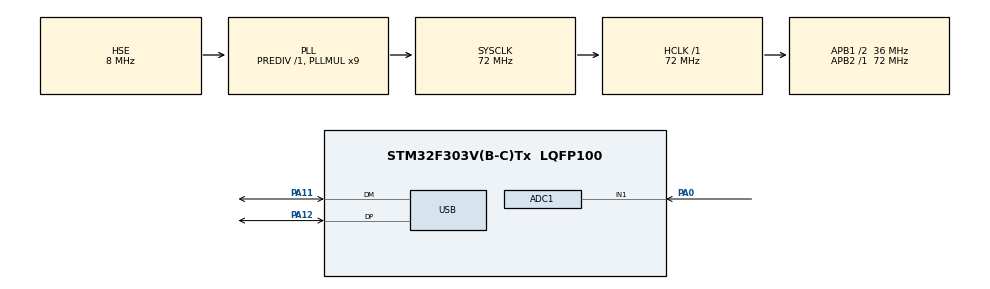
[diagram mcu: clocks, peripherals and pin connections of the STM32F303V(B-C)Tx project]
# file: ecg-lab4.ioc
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ADC1.Channel-0\#ChannelRegularConversion=ADC_CHANNEL_1
ADC1.ClockPrescaler=ADC_CLOCK_ASYNC_DIV1
ADC1.ContinuousConvMode=ENABLE
ADC1.DMAContinuousRequests=ENABLE
ADC1.ExternalTrigConv=ADC_EXTERNALTRIGCONV_T3_TRGO
ADC1.NbrOfConversionFlag=1
ADC1.Offset-0\#ChannelRegularConversion=0
ADC1.OffsetNumber-0\#ChannelRegularConversion=ADC_OFFSET_NONE
ADC1.Rank-0\#ChannelRegularConversion=1
ADC1.SamplingTime-0\#ChannelRegularConversion=ADC_SAMPLETIME_601CYCLES_5
ADC1.SamplingTimeOPAMP-0\#ChannelRegularConversion=ADC_SAMPLETIME_61CYCLES_5
ADC1.master=1
Dma.ADC1.0.Direction=DMA_PERIPH_TO_MEMORY
Dma.ADC1.0.Instance=DMA1_Channel1
Dma.ADC1.0.MemDataAlignment=DMA_MDATAALIGN_WORD
Dma.ADC1.0.MemInc=DMA_MINC_ENABLE
Dma.ADC1.0.Mode=DMA_CIRCULAR
Dma.ADC1.0.PeriphDataAlignment=DMA_PDATAALIGN_WORD
Dma.ADC1.0.PeriphInc=DMA_PINC_DISABLE
Dma.ADC1.0.Priority=DMA_PRIORITY_LOW
Dma.Request0=ADC1
Mcu.Family=STM32F3
Mcu.Name=STM32F303V(B-C)Tx
Mcu.Package=LQFP100
NVIC.DMA1_Channel1_IRQn=true\:0\:0\:false\:false\:true\:false\:true\:true
NVIC.PriorityGroup=NVIC_PRIORITYGROUP_0
NVIC.TIM3_IRQn=true\:0\:0\:false\:false\:true\:true\:true\:true
NVIC.USB_LP_CAN_RX0_IRQn=true\:0\:0\:false\:false\:true\:false\:true\:true
PA0.Mode=IN1-Single-Ended
PA0.Signal=ADC1_IN1
PA11.Mode=Device
PA11.Signal=USB_DM
PA12.Mode=Device
PA12.Signal=USB_DP
PF0-OSC_IN.Mode=HSE-External-Oscillator
PF0-OSC_IN.Signal=RCC_OSC_IN
PF1-OSC_OUT.Mode=HSE-External-Oscillator
PF1-OSC_OUT.Signal=RCC_OSC_OUT
ProjectManager.HeapSize=0x200
ProjectManager.StackSize=0x400
ProjectManager.TargetToolchain=MDK-ARM V5.32
RCC.AHBFreq_Value=72000000
RCC.APB1CLKDivider=RCC_HCLK_DIV2
RCC.APB1Freq_Value=36000000
RCC.APB1TimFreq_Value=72000000
RCC.APB2Freq_Value=72000000
RCC.APB2TimFreq_Value=72000000
RCC.CortexFreq_Value=72000000
RCC.HCLKFreq_Value=72000000
RCC.HSE_VALUE=8000000
RCC.HSI_VALUE=8000000
RCC.LSE_VALUE=32768
RCC.PLLMUL=RCC_PLL_MUL9
RCC.PRESCALERUSB=RCC_USBCLKSOURCE_PLL_DIV1_5
RCC.SYSCLKFreq_VALUE=72000000
RCC.SYSCLKSourceVirtual=RCC_SYSCLKSOURCE_PLLCLK
RCC.USBFreq_Value=48000000
TIM3.Period=71
TIM3.Prescaler=10000
TIM3.TIM_MasterOutputTrigger=TIM_TRGO_UPDATE
USB_DEVICE.CLASS_NAME_FS=CDC
USB_DEVICE.VirtualMode=Cdc
USB_DEVICE.VirtualModeFS=Cdc_FS
VP_TIM3_VS_ClockSourceINT.Mode=Internal
VP_USB_DEVICE_VS_USB_DEVICE_CDC_FS.Mode=CDC_FS
board=STM32F3DISCOVERY

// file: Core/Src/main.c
#include "main.h"
#include "usb_device.h"
#include "usbd_cdc_if.h"

ADC_HandleTypeDef hadc1;
DMA_HandleTypeDef hdma_adc1;

TIM_HandleTypeDef htim3;

void SystemClock_Config(void);
static void MX_GPIO_Init(void);
static void MX_DMA_Init(void);
static void MX_ADC1_Init(void);
static void MX_TIM3_Init(void);
uint32_t adc[1]={0};
uint8_t datos[2]={0,0};
void HAL_TIM_PeriodElapsedCallback(TIM_HandleTypeDef *htim){
	if(htim->Instance == htim3.Instance){
		datos[0] = (int)adc[0]/100;
		datos[1] = adc[0]-datos[0]*100;
		CDC_Transmit_FS(datos,sizeof(datos));
	}

}
int main(void)
{

  HAL_Init();
  SystemClock_Config();
  MX_GPIO_Init();
  MX_DMA_Init();
  MX_USB_DEVICE_Init();
  MX_ADC1_Init();
  MX_TIM3_Init();

	HAL_TIM_Base_Start_IT(&htim3);
	HAL_ADC_Start_DMA(&hadc1,adc,1);
  while (1)
  {

  }

}

void SystemClock_Config(void)
{
  RCC_OscInitTypeDef RCC_OscInitStruct = {0};
  RCC_ClkInitTypeDef RCC_ClkInitStruct = {0};
  RCC_PeriphCLKInitTypeDef PeriphClkInit = {0};

  /** Initializes the RCC Oscillators according to the specified parameters
  * in the RCC_OscInitTypeDef structure.
  */
  RCC_OscInitStruct.OscillatorType = RCC_OSCILLATORTYPE_HSE;
  RCC_OscInitStruct.HSEState = RCC_HSE_ON;
  RCC_OscInitStruct.HSEPredivValue = RCC_HSE_PREDIV_DIV1;
  RCC_OscInitStruct.HSIState = RCC_HSI_ON;
  RCC_OscInitStruct.PLL.PLLState = RCC_PLL_ON;
  RCC_OscInitStruct.PLL.PLLSource = RCC_PLLSOURCE_HSE;
  RCC_OscInitStruct.PLL.PLLMUL = RCC_PLL_MUL9;
  if (HAL_RCC_OscConfig(&RCC_OscInitStruct) != HAL_OK)
  {
    Error_Handler();
  }

  /** Initializes the CPU, AHB and APB buses clocks
  */
  RCC_ClkInitStruct.ClockType = RCC_CLOCKTYPE_HCLK|RCC_CLOCKTYPE_SYSCLK
                              |RCC_CLOCKTYPE_PCLK1|RCC_CLOCKTYPE_PCLK2;
  RCC_ClkInitStruct.SYSCLKSource = RCC_SYSCLKSOURCE_PLLCLK;
  RCC_ClkInitStruct.AHBCLKDivider = RCC_SYSCLK_DIV1;
  RCC_ClkInitStruct.APB1CLKDivider = RCC_HCLK_DIV2;
  RCC_ClkInitStruct.APB2CLKDivider = RCC_HCLK_DIV1;

  if (HAL_RCC_ClockConfig(&RCC_ClkInitStruct, FLASH_LATENCY_2) != HAL_OK)
  {
    Error_Handler();
  }
  PeriphClkInit.PeriphClockSelection = RCC_PERIPHCLK_USB|RCC_PERIPHCLK_ADC12;
  PeriphClkInit.Adc12ClockSelection = RCC_ADC12PLLCLK_DIV1;
  PeriphClkInit.USBClockSelection = RCC_USBCLKSOURCE_PLL_DIV1_5;
  if (HAL_RCCEx_PeriphCLKConfig(&PeriphClkInit) != HAL_OK)
  {
    Error_Handler();
  }
}

static void MX_ADC1_Init(void)
{

  ADC_MultiModeTypeDef multimode = {0};
  ADC_ChannelConfTypeDef sConfig = {0};

  /** Common config
  */
  hadc1.Instance = ADC1;
  hadc1.Init.ClockPrescaler = ADC_CLOCK_ASYNC_DIV1;
  hadc1.Init.Resolution = ADC_RESOLUTION_12B;
  hadc1.Init.ScanConvMode = ADC_SCAN_DISABLE;
  hadc1.Init.ContinuousConvMode = ENABLE;
  hadc1.Init.DiscontinuousConvMode = DISABLE;
  hadc1.Init.ExternalTrigConvEdge = ADC_EXTERNALTRIGCONVEDGE_RISING;
  hadc1.Init.ExternalTrigConv = ADC_EXTERNALTRIGCONV_T3_TRGO;
  hadc1.Init.DataAlign = ADC_DATAALIGN_RIGHT;
  hadc1.Init.NbrOfConversion = 1;
  hadc1.Init.DMAContinuousRequests = ENABLE;
  hadc1.Init.EOCSelection = ADC_EOC_SINGLE_CONV;
  hadc1.Init.LowPowerAutoWait = DISABLE;
  hadc1.Init.Overrun = ADC_OVR_DATA_OVERWRITTEN;
  if (HAL_ADC_Init(&hadc1) != HAL_OK)
  {
    Error_Handler();
  }

  /** Configure the ADC multi-mode
  */
  multimode.Mode = ADC_MODE_INDEPENDENT;
  if (HAL_ADCEx_MultiModeConfigChannel(&hadc1, &multimode) != HAL_OK)
  {
    Error_Handler();
  }

  /** Configure Regular Channel
  */
  sConfig.Channel = ADC_CHANNEL_1;
  sConfig.Rank = ADC_REGULAR_RANK_1;
  sConfig.SingleDiff = ADC_SINGLE_ENDED;
  sConfig.SamplingTime = ADC_SAMPLETIME_601CYCLES_5;
  sConfig.OffsetNumber = ADC_OFFSET_NONE;
  sConfig.Offset = 0;
  if (HAL_ADC_ConfigChannel(&hadc1, &sConfig) != HAL_OK)
  {
    Error_Handler();
  }

}

static void MX_TIM3_Init(void)
{

  TIM_ClockConfigTypeDef sClockSourceConfig = {0};
  TIM_MasterConfigTypeDef sMasterConfig = {0};

  htim3.Instance = TIM3;
  htim3.Init.Prescaler = 10000;
  htim3.Init.CounterMode = TIM_COUNTERMODE_UP;
  htim3.Init.Period = 71;
  htim3.Init.ClockDivision = TIM_CLOCKDIVISION_DIV1;
  htim3.Init.AutoReloadPreload = TIM_AUTORELOAD_PRELOAD_DISABLE;
  if (HAL_TIM_Base_Init(&htim3) != HAL_OK)
  {
    Error_Handler();
  }
  sClockSourceConfig.ClockSource = TIM_CLOCKSOURCE_INTERNAL;
  if (HAL_TIM_ConfigClockSource(&htim3, &sClockSourceConfig) != HAL_OK)
  {
    Error_Handler();
  }
  sMasterConfig.MasterOutputTrigger = TIM_TRGO_UPDATE;
  sMasterConfig.MasterSlaveMode = TIM_MASTERSLAVEMODE_DISABLE;
  if (HAL_TIMEx_MasterConfigSynchronization(&htim3, &sMasterConfig) != HAL_OK)
  {
    Error_Handler();
  }

}

static void MX_DMA_Init(void)
{

  /* DMA controller clock enable */
  __HAL_RCC_DMA1_CLK_ENABLE();

  /* DMA interrupt init */
  /* DMA1_Channel1_IRQn interrupt configuration */
  HAL_NVIC_SetPriority(DMA1_Channel1_IRQn, 0, 0);
  HAL_NVIC_EnableIRQ(DMA1_Channel1_IRQn);

}

static void MX_GPIO_Init(void)
{

  /* GPIO Ports Clock Enable */
  __HAL_RCC_GPIOF_CLK_ENABLE();
  __HAL_RCC_GPIOA_CLK_ENABLE();

}

/* USER CODE BEGIN 4 */
void CDC_ReceiveCallBack(uint8_t *buf, uint32_t len){

}

/* USER CODE END 4 */

void Error_Handler(void)
{
  __disable_irq();
  while (1)
  {
  }
}
